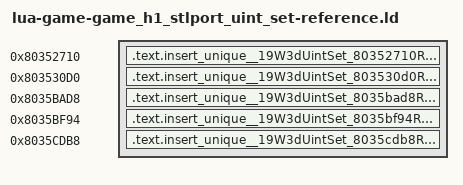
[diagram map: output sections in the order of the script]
/* Generated reference-only placements. All bodies are source-built. */
OUTPUT_FORMAT("elf32-powerpc")
OUTPUT_ARCH(powerpc)
ENTRY(insert_unique__19W3dUintSet_80352710RCUi)
_SDA_BASE_ = 0x804b2540;
_SDA2_BASE_ = 0x804c2540;
insert_node__19W3dUintSet_80352710P9W3dRbNodeT1RCUiT1 = 0x8035256c;
insert_node__19W3dUintSet_803530d0P9W3dRbNodeT1RCUiT1 = 0x80352f8c;
insert_node__19W3dUintSet_8035bad8P9W3dRbNodeT1RCUiT1 = 0x8035b994;
insert_node__19W3dUintSet_8035bf94P9W3dRbNodeT1RCUiT1 = 0x8035be10;
insert_node__19W3dUintSet_8035cdb8P9W3dRbNodeT1RCUiT1 = 0x8035cc74;
w3d_rb_decrement_803526a0 = 0x803526a0;
SECTIONS {
  .text.insert_unique__19W3dUintSet_80352710RCUi 0x80352710 : { *(.text.insert_unique__19W3dUintSet_80352710RCUi) }
  .text.insert_unique__19W3dUintSet_803530d0RCUi 0x803530d0 : { *(.text.insert_unique__19W3dUintSet_803530d0RCUi) }
  .text.insert_unique__19W3dUintSet_8035bad8RCUi 0x8035bad8 : { *(.text.insert_unique__19W3dUintSet_8035bad8RCUi) }
  .text.insert_unique__19W3dUintSet_8035bf94RCUi 0x8035bf94 : { *(.text.insert_unique__19W3dUintSet_8035bf94RCUi) }
  .text.insert_unique__19W3dUintSet_8035cdb8RCUi 0x8035cdb8 : { *(.text.insert_unique__19W3dUintSet_8035cdb8RCUi) }
  /DISCARD/ : { *(.text*) *(.rodata*) *(.data*) *(.bss*) *(.sdata*) *(.sbss*) *(.comment) }
}
